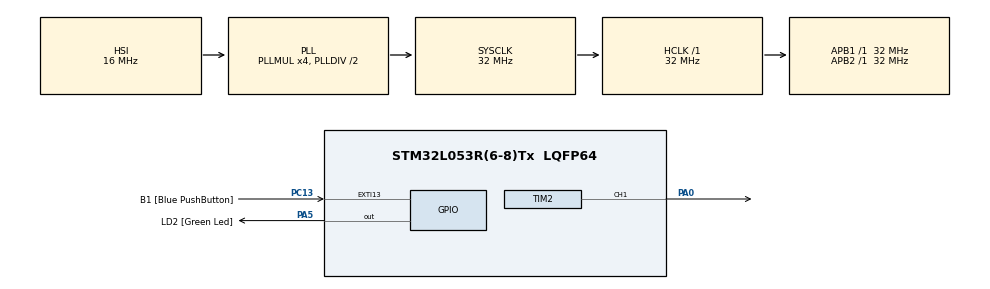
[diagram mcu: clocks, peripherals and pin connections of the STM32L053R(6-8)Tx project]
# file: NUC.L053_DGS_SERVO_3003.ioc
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Mcu.Family=STM32L0
Mcu.Name=STM32L053R(6-8)Tx
Mcu.Package=LQFP64
PA0.Signal=S_TIM2_CH1
PA13.GPIO_Label=TMS
PA13.Mode=Serial_Wire
PA13.Signal=SYS_SWDIO
PA14.GPIO_Label=TCK
PA14.Mode=Serial_Wire
PA14.Signal=SYS_SWCLK
PA2.GPIO_Label=USART_TX
PA2.Signal=USART2_TX
PA3.GPIO_Label=USART_RX
PA3.Signal=USART2_RX
PA5.GPIO_Label=LD2 [Green Led]
PA5.Signal=GPIO_Output
PC13.GPIO_Label=B1 [Blue PushButton]
PC13.GPIO_ModeDefaultEXTI=GPIO_MODE_IT_FALLING
PC13.Signal=GPXTI13
PC14-OSC32_IN.Signal=RCC_OSC32_IN
PC15-OSC32_OUT.Signal=RCC_OSC32_OUT
PH0-OSC_IN.Signal=RCC_OSC_IN
PH1-OSC_OUT.Signal=RCC_OSC_OUT
ProjectManager.HeapSize=0x200
ProjectManager.StackSize=0x400
ProjectManager.TargetToolchain=STM32CubeIDE
RCC.AHBFreq_Value=32000000
RCC.APB1Freq_Value=32000000
RCC.APB1TimFreq_Value=32000000
RCC.APB2Freq_Value=32000000
RCC.APB2TimFreq_Value=32000000
RCC.HCLKFreq_Value=32000000
RCC.HSE_VALUE=8000000
RCC.HSI16_VALUE=16000000
RCC.HSI48_VALUE=48000000
RCC.HSI_VALUE=16000000
RCC.LSEState=RCC_LSE_ON
RCC.LSE_VALUE=32768
RCC.MSI_VALUE=2097000
RCC.PLLMUL=RCC_PLLMUL_4
RCC.SYSCLKFreq_VALUE=32000000
RCC.SYSCLKSource=RCC_SYSCLKSOURCE_PLLCLK
RCC.VCOOutputFreq_Value=64000000
SH.S_TIM2_CH1.0=TIM2_CH1,PWM Generation1 CH1
TIM2.Channel-PWM\ Generation1\ CH1=TIM_CHANNEL_1
TIM2.Period=19999
TIM2.Prescaler=32-1
board=NUCLEO-L053R8

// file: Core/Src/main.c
/* USER CODE BEGIN Header */
/**
  ******************************************************************************
  * @file           : main.c
  * @brief          : Main program body
  ******************************************************************************
  * @attention
  *
  * Copyright (c) 2023 STMicroelectronics.
  * All rights reserved.
  *
  * This software is licensed under terms that can be found in the LICENSE file
  * in the root directory of this software component.
  * If no LICENSE file comes with this software, it is provided AS-IS.
  *
  ******************************************************************************
  */
/* USER CODE END Header */
#include "main.h"

TIM_HandleTypeDef htim2;

void SystemClock_Config(void);
static void MX_GPIO_Init(void);
static void MX_TIM2_Init(void);

int main(void)
{

  /* MCU Configuration--------------------------------------------------------*/

  /* Reset of all peripherals, Initializes the Flash interface and the Systick. */
  HAL_Init();

  /* Configure the system clock */
  SystemClock_Config();

  /* Initialize all configured peripherals */
  MX_GPIO_Init();
  MX_TIM2_Init();
  /* USER CODE BEGIN 2 */
  HAL_TIM_PWM_Start(&htim2, TIM_CHANNEL_1);
  /* USER CODE END 2 */

  /* Infinite loop */
  /* USER CODE BEGIN WHILE */
  while (1)
  {

	  for(int i =400;i<=2500;i++){
	  __HAL_TIM_SET_COMPARE(&htim2, TIM_CHANNEL_1, i);
	  HAL_Delay(1);
	  }
    /* USER CODE END WHILE */

  }
}

void SystemClock_Config(void)
{
  RCC_OscInitTypeDef RCC_OscInitStruct = {0};
  RCC_ClkInitTypeDef RCC_ClkInitStruct = {0};

  /** Configure the main internal regulator output voltage
  */
  __HAL_PWR_VOLTAGESCALING_CONFIG(PWR_REGULATOR_VOLTAGE_SCALE1);

  /** Initializes the RCC Oscillators according to the specified parameters
  * in the RCC_OscInitTypeDef structure.
  */
  RCC_OscInitStruct.OscillatorType = RCC_OSCILLATORTYPE_HSI;
  RCC_OscInitStruct.HSIState = RCC_HSI_ON;
  RCC_OscInitStruct.HSICalibrationValue = RCC_HSICALIBRATION_DEFAULT;
  RCC_OscInitStruct.PLL.PLLState = RCC_PLL_ON;
  RCC_OscInitStruct.PLL.PLLSource = RCC_PLLSOURCE_HSI;
  RCC_OscInitStruct.PLL.PLLMUL = RCC_PLLMUL_4;
  RCC_OscInitStruct.PLL.PLLDIV = RCC_PLLDIV_2;
  if (HAL_RCC_OscConfig(&RCC_OscInitStruct) != HAL_OK)
  {
    Error_Handler();
  }

  /** Initializes the CPU, AHB and APB buses clocks
  */
  RCC_ClkInitStruct.ClockType = RCC_CLOCKTYPE_HCLK|RCC_CLOCKTYPE_SYSCLK
                              |RCC_CLOCKTYPE_PCLK1|RCC_CLOCKTYPE_PCLK2;
  RCC_ClkInitStruct.SYSCLKSource = RCC_SYSCLKSOURCE_PLLCLK;
  RCC_ClkInitStruct.AHBCLKDivider = RCC_SYSCLK_DIV1;
  RCC_ClkInitStruct.APB1CLKDivider = RCC_HCLK_DIV1;
  RCC_ClkInitStruct.APB2CLKDivider = RCC_HCLK_DIV1;

  if (HAL_RCC_ClockConfig(&RCC_ClkInitStruct, FLASH_LATENCY_1) != HAL_OK)
  {
    Error_Handler();
  }
}

static void MX_TIM2_Init(void)
{

  TIM_MasterConfigTypeDef sMasterConfig = {0};
  TIM_OC_InitTypeDef sConfigOC = {0};

  htim2.Instance = TIM2;
  htim2.Init.Prescaler = 32-1;
  htim2.Init.CounterMode = TIM_COUNTERMODE_UP;
  htim2.Init.Period = 19999;
  htim2.Init.ClockDivision = TIM_CLOCKDIVISION_DIV1;
  htim2.Init.AutoReloadPreload = TIM_AUTORELOAD_PRELOAD_DISABLE;
  if (HAL_TIM_PWM_Init(&htim2) != HAL_OK)
  {
    Error_Handler();
  }
  sMasterConfig.MasterOutputTrigger = TIM_TRGO_RESET;
  sMasterConfig.MasterSlaveMode = TIM_MASTERSLAVEMODE_DISABLE;
  if (HAL_TIMEx_MasterConfigSynchronization(&htim2, &sMasterConfig) != HAL_OK)
  {
    Error_Handler();
  }
  sConfigOC.OCMode = TIM_OCMODE_PWM1;
  sConfigOC.Pulse = 0;
  sConfigOC.OCPolarity = TIM_OCPOLARITY_HIGH;
  sConfigOC.OCFastMode = TIM_OCFAST_DISABLE;
  if (HAL_TIM_PWM_ConfigChannel(&htim2, &sConfigOC, TIM_CHANNEL_1) != HAL_OK)
  {
    Error_Handler();
  }
  HAL_TIM_MspPostInit(&htim2);

}

static void MX_GPIO_Init(void)
{
  GPIO_InitTypeDef GPIO_InitStruct = {0};

  /* GPIO Ports Clock Enable */
  __HAL_RCC_GPIOC_CLK_ENABLE();
  __HAL_RCC_GPIOH_CLK_ENABLE();
  __HAL_RCC_GPIOA_CLK_ENABLE();

  /*Configure GPIO pin Output Level */
  HAL_GPIO_WritePin(LD2_GPIO_Port, LD2_Pin, GPIO_PIN_RESET);

  /*Configure GPIO pin : B1_Pin */
  GPIO_InitStruct.Pin = B1_Pin;
  GPIO_InitStruct.Mode = GPIO_MODE_IT_FALLING;
  GPIO_InitStruct.Pull = GPIO_NOPULL;
  HAL_GPIO_Init(B1_GPIO_Port, &GPIO_InitStruct);

  /*Configure GPIO pins : USART_TX_Pin USART_RX_Pin */
  GPIO_InitStruct.Pin = USART_TX_Pin|USART_RX_Pin;
  GPIO_InitStruct.Mode = GPIO_MODE_AF_PP;
  GPIO_InitStruct.Pull = GPIO_NOPULL;
  GPIO_InitStruct.Speed = GPIO_SPEED_FREQ_VERY_HIGH;
  GPIO_InitStruct.Alternate = GPIO_AF4_USART2;
  HAL_GPIO_Init(GPIOA, &GPIO_InitStruct);

  /*Configure GPIO pin : LD2_Pin */
  GPIO_InitStruct.Pin = LD2_Pin;
  GPIO_InitStruct.Mode = GPIO_MODE_OUTPUT_PP;
  GPIO_InitStruct.Pull = GPIO_NOPULL;
  GPIO_InitStruct.Speed = GPIO_SPEED_FREQ_LOW;
  HAL_GPIO_Init(LD2_GPIO_Port, &GPIO_InitStruct);

}

void Error_Handler(void)
{
  __disable_irq();
  while (1)
  {
  }
}
